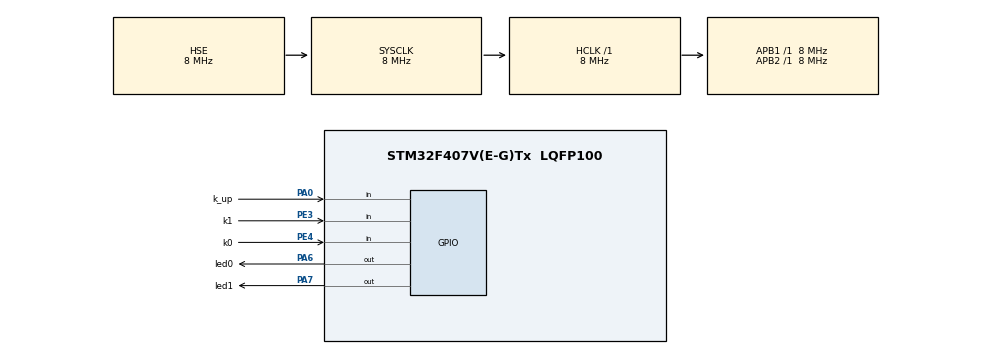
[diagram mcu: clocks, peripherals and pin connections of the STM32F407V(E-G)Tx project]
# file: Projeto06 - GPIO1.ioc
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Mcu.Family=STM32F4
Mcu.Name=STM32F407V(E-G)Tx
Mcu.Package=LQFP100
NVIC.PriorityGroup=NVIC_PRIORITYGROUP_4
PA0-WKUP.GPIO_Label=k_up
PA0-WKUP.GPIO_PuPd=GPIO_PULLDOWN
PA0-WKUP.Signal=GPIO_Input
PA6.GPIO_Label=led0
PA6.PinState=GPIO_PIN_SET
PA6.Signal=GPIO_Output
PA7.GPIO_Label=led1
PA7.PinState=GPIO_PIN_RESET
PA7.Signal=GPIO_Output
PE3.GPIO_Label=k1
PE3.GPIO_PuPd=GPIO_PULLUP
PE3.Signal=GPIO_Input
PE4.GPIO_Label=k0
PE4.GPIO_PuPd=GPIO_PULLUP
PE4.Signal=GPIO_Input
PH0-OSC_IN.Mode=HSE-External-Oscillator
PH0-OSC_IN.Signal=RCC_OSC_IN
PH1-OSC_OUT.Mode=HSE-External-Oscillator
PH1-OSC_OUT.Signal=RCC_OSC_OUT
ProjectManager.HeapSize=0x200
ProjectManager.StackSize=0x400
ProjectManager.TargetToolchain=STM32CubeIDE
RCC.AHBFreq_Value=8000000
RCC.APB1Freq_Value=8000000
RCC.APB1TimFreq_Value=8000000
RCC.APB2Freq_Value=8000000
RCC.APB2TimFreq_Value=8000000
RCC.CortexFreq_Value=8000000
RCC.HCLKFreq_Value=8000000
RCC.HSE_VALUE=8000000
RCC.HSI_VALUE=16000000
RCC.LSE_VALUE=32768
RCC.SYSCLKFreq_VALUE=8000000
RCC.SYSCLKSource=RCC_SYSCLKSOURCE_HSE
RCC.VCOOutputFreq_Value=192000000
board=custom

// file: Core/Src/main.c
/* USER CODE BEGIN Header */
/**
  ******************************************************************************
  * @file           : main.c
  * @brief          : Main program body
  ******************************************************************************
  * @attention
  *
  * Copyright (c) 2022 STMicroelectronics.
  * All rights reserved.
  *
  * This software is licensed under terms that can be found in the LICENSE file
  * in the root directory of this software component.
  * If no LICENSE file comes with this software, it is provided AS-IS.
  *
  ******************************************************************************
  */
/* USER CODE END Header */
#include "main.h"

void SystemClock_Config(void);
static void MX_GPIO_Init(void);

int main(void)
{

  /* MCU Configuration--------------------------------------------------------*/

  /* Reset of all peripherals, Initializes the Flash interface and the Systick. */
  HAL_Init();

  /* Configure the system clock */
  SystemClock_Config();

  /* Initialize all configured peripherals */
  MX_GPIO_Init();

  /* Infinite loop */
  /* USER CODE BEGIN WHILE */
  while (1)
  {
	  HAL_GPIO_TogglePin(led0_GPIO_Port, led0_Pin);
	  HAL_GPIO_TogglePin(led1_GPIO_Port, led1_Pin);

	  if (HAL_GPIO_ReadPin(k_up_GPIO_Port, k_up_Pin) == GPIO_PIN_SET)
	  {
		  HAL_Delay(200);

		  if (HAL_GPIO_ReadPin(k_up_GPIO_Port, k_up_Pin) == GPIO_PIN_SET)
		  {
			  HAL_GPIO_TogglePin(led1_GPIO_Port, led1_Pin);
		  }
	  }

	  HAL_Delay(500);
    /* USER CODE END WHILE */

  }
}

void SystemClock_Config(void)
{
  RCC_OscInitTypeDef RCC_OscInitStruct = {0};
  RCC_ClkInitTypeDef RCC_ClkInitStruct = {0};

  /** Configure the main internal regulator output voltage
  */
  __HAL_RCC_PWR_CLK_ENABLE();
  __HAL_PWR_VOLTAGESCALING_CONFIG(PWR_REGULATOR_VOLTAGE_SCALE1);

  /** Initializes the RCC Oscillators according to the specified parameters
  * in the RCC_OscInitTypeDef structure.
  */
  RCC_OscInitStruct.OscillatorType = RCC_OSCILLATORTYPE_HSE;
  RCC_OscInitStruct.HSEState = RCC_HSE_ON;
  RCC_OscInitStruct.PLL.PLLState = RCC_PLL_NONE;
  if (HAL_RCC_OscConfig(&RCC_OscInitStruct) != HAL_OK)
  {
    Error_Handler();
  }

  /** Initializes the CPU, AHB and APB buses clocks
  */
  RCC_ClkInitStruct.ClockType = RCC_CLOCKTYPE_HCLK|RCC_CLOCKTYPE_SYSCLK
                              |RCC_CLOCKTYPE_PCLK1|RCC_CLOCKTYPE_PCLK2;
  RCC_ClkInitStruct.SYSCLKSource = RCC_SYSCLKSOURCE_HSE;
  RCC_ClkInitStruct.AHBCLKDivider = RCC_SYSCLK_DIV1;
  RCC_ClkInitStruct.APB1CLKDivider = RCC_HCLK_DIV1;
  RCC_ClkInitStruct.APB2CLKDivider = RCC_HCLK_DIV1;

  if (HAL_RCC_ClockConfig(&RCC_ClkInitStruct, FLASH_LATENCY_0) != HAL_OK)
  {
    Error_Handler();
  }
}

static void MX_GPIO_Init(void)
{
  GPIO_InitTypeDef GPIO_InitStruct = {0};

  /* GPIO Ports Clock Enable */
  __HAL_RCC_GPIOE_CLK_ENABLE();
  __HAL_RCC_GPIOH_CLK_ENABLE();
  __HAL_RCC_GPIOA_CLK_ENABLE();

  /*Configure GPIO pin Output Level */
  HAL_GPIO_WritePin(led0_GPIO_Port, led0_Pin, GPIO_PIN_SET);

  /*Configure GPIO pin Output Level */
  HAL_GPIO_WritePin(led1_GPIO_Port, led1_Pin, GPIO_PIN_RESET);

  /*Configure GPIO pins : k1_Pin k0_Pin */
  GPIO_InitStruct.Pin = k1_Pin|k0_Pin;
  GPIO_InitStruct.Mode = GPIO_MODE_INPUT;
  GPIO_InitStruct.Pull = GPIO_PULLUP;
  HAL_GPIO_Init(GPIOE, &GPIO_InitStruct);

  /*Configure GPIO pin : k_up_Pin */
  GPIO_InitStruct.Pin = k_up_Pin;
  GPIO_InitStruct.Mode = GPIO_MODE_INPUT;
  GPIO_InitStruct.Pull = GPIO_PULLDOWN;
  HAL_GPIO_Init(k_up_GPIO_Port, &GPIO_InitStruct);

  /*Configure GPIO pins : led0_Pin led1_Pin */
  GPIO_InitStruct.Pin = led0_Pin|led1_Pin;
  GPIO_InitStruct.Mode = GPIO_MODE_OUTPUT_PP;
  GPIO_InitStruct.Pull = GPIO_NOPULL;
  GPIO_InitStruct.Speed = GPIO_SPEED_FREQ_LOW;
  HAL_GPIO_Init(GPIOA, &GPIO_InitStruct);

}

void Error_Handler(void)
{
  __disable_irq();
  while (1)
  {
  }
}
